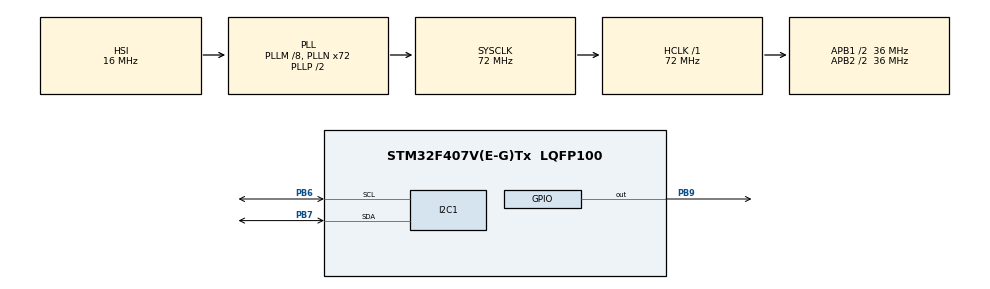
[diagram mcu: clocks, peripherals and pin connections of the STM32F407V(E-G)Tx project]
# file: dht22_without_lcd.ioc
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Mcu.Family=STM32F4
Mcu.Name=STM32F407V(E-G)Tx
Mcu.Package=LQFP100
NVIC.PriorityGroup=NVIC_PRIORITYGROUP_0
PA13.Mode=Serial_Wire
PA13.Signal=SYS_JTMS-SWDIO
PA14.Mode=Serial_Wire
PA14.Signal=SYS_JTCK-SWCLK
PB6.Mode=I2C
PB6.Signal=I2C1_SCL
PB7.Mode=I2C
PB7.Signal=I2C1_SDA
PB9.Signal=GPIO_Output
PH0-OSC_IN.Mode=HSE-External-Oscillator
PH0-OSC_IN.Signal=RCC_OSC_IN
PH1-OSC_OUT.Mode=HSE-External-Oscillator
PH1-OSC_OUT.Signal=RCC_OSC_OUT
ProjectManager.HeapSize=0x200
ProjectManager.StackSize=0x400
ProjectManager.TargetToolchain=STM32CubeIDE
RCC.48MHZClocksFreq_Value=20571428.57142857
RCC.AHBFreq_Value=72000000
RCC.APB1CLKDivider=RCC_HCLK_DIV2
RCC.APB1Freq_Value=36000000
RCC.APB1TimFreq_Value=72000000
RCC.APB2CLKDivider=RCC_HCLK_DIV2
RCC.APB2Freq_Value=36000000
RCC.APB2TimFreq_Value=72000000
RCC.CortexFreq_Value=72000000
RCC.HCLKFreq_Value=72000000
RCC.HSE_VALUE=8000000
RCC.HSI_VALUE=16000000
RCC.LSE_VALUE=32768
RCC.PLLM=8
RCC.PLLN=72
RCC.PLLQ=7
RCC.SYSCLKFreq_VALUE=72000000
RCC.SYSCLKSource=RCC_SYSCLKSOURCE_PLLCLK
RCC.VCOOutputFreq_Value=144000000
TIM1.Prescaler=71
VP_TIM1_VS_ClockSourceINT.Mode=Internal
board=STM32F407G-DISC1

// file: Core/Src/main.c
/* USER CODE BEGIN Header */
/**
 ******************************************************************************
 * @file           : main.c
 * @brief          : Main program body
 ******************************************************************************
 * @attention
 *
 * Copyright (c) 2024 STMicroelectronics.
 * All rights reserved.
 *
 * This software is licensed under terms that can be found in the LICENSE file
 * in the root directory of this software component.
 * If no LICENSE file comes with this software, it is provided AS-IS.
 *
 ******************************************************************************
 */
/* USER CODE END Header */
#include "main.h"

/* USER CODE BEGIN Includes */
#include "lcd16x2_i2c.h"
#include <string.h>
/* USER CODE END Includes */

I2C_HandleTypeDef hi2c1;

TIM_HandleTypeDef htim1;

void SystemClock_Config(void);
static void MX_GPIO_Init(void);
static void MX_TIM1_Init(void);
static void MX_I2C1_Init(void);

/* USER CODE BEGIN 0 */
#define DHT22_PORT GPIOB
#define DHT22_PIN GPIO_PIN_9
uint8_t RH1, RH2, TC1, TC2, SUM, CHECK;
uint32_t pMillis, cMillis;
float tCelsius = 0;
float tFahrenheit = 0;
int RH = 0;

void microDelay(uint16_t delay) {
	__HAL_TIM_SET_COUNTER(&htim1, 0);
	while (__HAL_TIM_GET_COUNTER(&htim1) < delay)
		;
}

uint8_t DHT22_Start(void) {
	uint8_t Response = 0;
	GPIO_InitTypeDef GPIO_InitStructPrivate = { 0 };
	GPIO_InitStructPrivate.Pin = DHT22_PIN;
	GPIO_InitStructPrivate.Mode = GPIO_MODE_OUTPUT_PP;
	GPIO_InitStructPrivate.Speed = GPIO_SPEED_FREQ_LOW;
	GPIO_InitStructPrivate.Pull = GPIO_NOPULL;
	HAL_GPIO_Init(DHT22_PORT, &GPIO_InitStructPrivate); // set the pin as output
	HAL_GPIO_WritePin(DHT22_PORT, DHT22_PIN, 0);   // pull the pin low
	microDelay(1300);   // wait for 1300us
	HAL_GPIO_WritePin(DHT22_PORT, DHT22_PIN, 1);   // pull the pin high
	microDelay(30);   // wait for 30us
	GPIO_InitStructPrivate.Mode = GPIO_MODE_INPUT;
	GPIO_InitStructPrivate.Pull = GPIO_PULLUP;
	HAL_GPIO_Init(DHT22_PORT, &GPIO_InitStructPrivate); // set the pin as input
	microDelay(40);
	if (!(HAL_GPIO_ReadPin(DHT22_PORT, DHT22_PIN))) {
		microDelay(80);
		if ((HAL_GPIO_ReadPin(DHT22_PORT, DHT22_PIN)))
			Response = 1;
	}
	pMillis = HAL_GetTick();
	cMillis = HAL_GetTick();
	while ((HAL_GPIO_ReadPin(DHT22_PORT, DHT22_PIN)) && pMillis + 2 > cMillis) {
		cMillis = HAL_GetTick();
	}
	return Response;
}

uint8_t DHT22_Read(void) {
	uint8_t a, b;
	for (a = 0; a < 8; a++) {
		pMillis = HAL_GetTick();
		cMillis = HAL_GetTick();
		while (!(HAL_GPIO_ReadPin(DHT22_PORT, DHT22_PIN))
				&& pMillis + 2 > cMillis) {  // wait for the pin to go high
			cMillis = HAL_GetTick();
		}
		microDelay(40);   // wait for 40 us
		if (!(HAL_GPIO_ReadPin(DHT22_PORT, DHT22_PIN)))   // if the pin is low
			b &= ~(1 << (7 - a));
		else
			b |= (1 << (7 - a));
		pMillis = HAL_GetTick();
		cMillis = HAL_GetTick();
		while ((HAL_GPIO_ReadPin(DHT22_PORT, DHT22_PIN))
				&& pMillis + 2 > cMillis) {  // wait for the pin to go low
			cMillis = HAL_GetTick();
		}
	}
	return b;
}
/* USER CODE END 0 */

int main(void) {

	/* USER CODE BEGIN 1 */
	char str0[64];
	char str1[64];
	/* USER CODE END 1 */

	/* MCU Configuration--------------------------------------------------------*/

	/* Reset of all peripherals, Initializes the Flash interface and the Systick. */
	HAL_Init();

	/* Configure the system clock */
	SystemClock_Config();

	/* Initialize all configured peripherals */
	MX_GPIO_Init();
	MX_TIM1_Init();
	MX_I2C1_Init();
	/* USER CODE BEGIN 2 */
	HAL_TIM_Base_Start(&htim1);

	/* USER CODE END 2 */

	/* Infinite loop */
	while (1) {

		if (DHT22_Start()) {
			RH1 = DHT22_Read(); // First 8bits of humidity
			RH2 = DHT22_Read(); // Second 8bits of Relative humidity
			TC1 = DHT22_Read(); // First 8bits of Celsius
			TC2 = DHT22_Read(); // Second 8bits of Celsius
			SUM = DHT22_Read(); // Check sum
			CHECK = RH1 + RH2 + TC1 + TC2;
			if (CHECK == SUM) {
				if (TC1 > 127) // If TC1=10000000, negative temperature
						{
					tCelsius = (float) TC2 / 10 * (-1);
				} else {
					tCelsius = (float) ((TC1 << 8) | TC2) / 10;
				}
				//tFahrenheit = (float) (tCelsius * 9 / 5 + 32);
				tFahrenheit = (int) (tCelsius * 9 / 5 + 32)*10;
				//RH = (float) ((RH1 << 8) | RH2) / 10;
				RH = (int) ((RH1 << 8) | RH2);
			}
		}

		int ret = lcd16x2_i2c_init(&hi2c1);
		DHT22_Read();
		sprintf(str0, "temperature : %d \r \n",tFahrenheit);
		sprintf(str1, "humidity : %d \r \n",RH);
		if(ret)
		{
			lcd16x2_i2c_setCursor(0, 0);
			lcd16x2_i2c_printf(str0);
			lcd16x2_i2c_setCursor(1, 0);
			lcd16x2_i2c_printf(str1);
		}

		HAL_Delay(1000);

	}
}

void SystemClock_Config(void) {
	RCC_OscInitTypeDef RCC_OscInitStruct = { 0 };
	RCC_ClkInitTypeDef RCC_ClkInitStruct = { 0 };

	/** Configure the main internal regulator output voltage
	 */
	__HAL_RCC_PWR_CLK_ENABLE();
	__HAL_PWR_VOLTAGESCALING_CONFIG(PWR_REGULATOR_VOLTAGE_SCALE1);

	/** Initializes the RCC Oscillators according to the specified parameters
	 * in the RCC_OscInitTypeDef structure.
	 */
	RCC_OscInitStruct.OscillatorType = RCC_OSCILLATORTYPE_HSI;
	RCC_OscInitStruct.HSIState = RCC_HSI_ON;
	RCC_OscInitStruct.HSICalibrationValue = RCC_HSICALIBRATION_DEFAULT;
	RCC_OscInitStruct.PLL.PLLState = RCC_PLL_ON;
	RCC_OscInitStruct.PLL.PLLSource = RCC_PLLSOURCE_HSI;
	RCC_OscInitStruct.PLL.PLLM = 8;
	RCC_OscInitStruct.PLL.PLLN = 72;
	RCC_OscInitStruct.PLL.PLLP = RCC_PLLP_DIV2;
	RCC_OscInitStruct.PLL.PLLQ = 7;
	if (HAL_RCC_OscConfig(&RCC_OscInitStruct) != HAL_OK) {
		Error_Handler();
	}

	/** Initializes the CPU, AHB and APB buses clocks
	 */
	RCC_ClkInitStruct.ClockType = RCC_CLOCKTYPE_HCLK | RCC_CLOCKTYPE_SYSCLK
			| RCC_CLOCKTYPE_PCLK1 | RCC_CLOCKTYPE_PCLK2;
	RCC_ClkInitStruct.SYSCLKSource = RCC_SYSCLKSOURCE_PLLCLK;
	RCC_ClkInitStruct.AHBCLKDivider = RCC_SYSCLK_DIV1;
	RCC_ClkInitStruct.APB1CLKDivider = RCC_HCLK_DIV2;
	RCC_ClkInitStruct.APB2CLKDivider = RCC_HCLK_DIV2;

	if (HAL_RCC_ClockConfig(&RCC_ClkInitStruct, FLASH_LATENCY_2) != HAL_OK) {
		Error_Handler();
	}
}

static void MX_I2C1_Init(void) {

	hi2c1.Instance = I2C1;
	hi2c1.Init.ClockSpeed = 100000;
	hi2c1.Init.DutyCycle = I2C_DUTYCYCLE_2;
	hi2c1.Init.OwnAddress1 = 0;
	hi2c1.Init.AddressingMode = I2C_ADDRESSINGMODE_7BIT;
	hi2c1.Init.DualAddressMode = I2C_DUALADDRESS_DISABLE;
	hi2c1.Init.OwnAddress2 = 0;
	hi2c1.Init.GeneralCallMode = I2C_GENERALCALL_DISABLE;
	hi2c1.Init.NoStretchMode = I2C_NOSTRETCH_DISABLE;
	if (HAL_I2C_Init(&hi2c1) != HAL_OK) {
		Error_Handler();
	}

}

static void MX_TIM1_Init(void) {

	TIM_ClockConfigTypeDef sClockSourceConfig = { 0 };
	TIM_MasterConfigTypeDef sMasterConfig = { 0 };

	htim1.Instance = TIM1;
	htim1.Init.Prescaler = 71;
	htim1.Init.CounterMode = TIM_COUNTERMODE_UP;
	htim1.Init.Period = 65535;
	htim1.Init.ClockDivision = TIM_CLOCKDIVISION_DIV1;
	htim1.Init.RepetitionCounter = 0;
	htim1.Init.AutoReloadPreload = TIM_AUTORELOAD_PRELOAD_DISABLE;
	if (HAL_TIM_Base_Init(&htim1) != HAL_OK) {
		Error_Handler();
	}
	sClockSourceConfig.ClockSource = TIM_CLOCKSOURCE_INTERNAL;
	if (HAL_TIM_ConfigClockSource(&htim1, &sClockSourceConfig) != HAL_OK) {
		Error_Handler();
	}
	sMasterConfig.MasterOutputTrigger = TIM_TRGO_RESET;
	sMasterConfig.MasterSlaveMode = TIM_MASTERSLAVEMODE_DISABLE;
	if (HAL_TIMEx_MasterConfigSynchronization(&htim1, &sMasterConfig)
			!= HAL_OK) {
		Error_Handler();
	}

}

static void MX_GPIO_Init(void) {
	GPIO_InitTypeDef GPIO_InitStruct = { 0 };

	/* GPIO Ports Clock Enable */
	__HAL_RCC_GPIOH_CLK_ENABLE();
	__HAL_RCC_GPIOA_CLK_ENABLE();
	__HAL_RCC_GPIOB_CLK_ENABLE();

	/*Configure GPIO pin Output Level */
	HAL_GPIO_WritePin(GPIOB, GPIO_PIN_9, GPIO_PIN_RESET);

	/*Configure GPIO pin : PB9 */
	GPIO_InitStruct.Pin = GPIO_PIN_9;
	GPIO_InitStruct.Mode = GPIO_MODE_OUTPUT_PP;
	GPIO_InitStruct.Pull = GPIO_NOPULL;
	GPIO_InitStruct.Speed = GPIO_SPEED_FREQ_LOW;
	HAL_GPIO_Init(GPIOB, &GPIO_InitStruct);

}

void Error_Handler(void) {
	__disable_irq();
	while (1) {
	}
}
